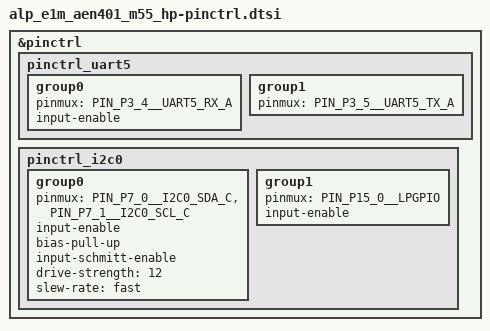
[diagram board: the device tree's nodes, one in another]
/*
 * Copyright (c) 2026 Alp Lab AB
 * SPDX-License-Identifier: Apache-2.0
 *
 * E1M-AEN401 (Alif Ensemble E4) Cortex-M55-HP carrier pin control.
 *
 * Console: the E1M edge "UART0" maps to Alif UART5 (P3_4 RX_A / P3_5 TX_A)
 * on the AEN module PCB; the Alp E1M-EVK carrier wires its USB-UART console
 * to it.  Confirmed against the shared AEN-family SoM pinout (common with
 * AEN801 -- same E1M connector mapping).
 *
 * BRD_I2C (the on-module RV-3028 / TMP112 bus) and the RV-3028 alarm pad are
 * copied from the generated AEN803 pin control: the AEN SKUs share one SoM
 * PCB.  Other pin groups are added alongside their drivers.
 */

#include <zephyr/dt-bindings/pinctrl/alif-ensemble-pinctrl.h>

&pinctrl {
	pinctrl_uart5: pinctrl_uart5 {
		group0 {
			pinmux = <PIN_P3_4__UART5_RX_A>;
			input-enable;
		};

		group1 {
			pinmux = <PIN_P3_5__UART5_TX_A>;
		};
	};
	/*
	 * BRD_I2C = SoC I2C0 function C: P7_0 SDA / P7_1 SCL,
	 * the on-module housekeeping bus (see the board .dts for the parts on it).
	 *
	 * BOTH pins get input-enable, in one group -- Alif's own DFP sets
	 * PADCTRL_READ_ENABLE on P7_0 AND P7_1.  With it on SDA only, the
	 * i2c_dw controller cannot SENSE SCL (clock-stretch detect / arbitration)
	 * and NACKs every address for a reason that looks electrical but is not.
	 *
	 * bias-pull-up is DSC=1, a REAL pull-up: pinctrl_soc.h's field comment
	 * (soc/alif/ensemble/pinctrl_soc.h:24) and its ALIF_PINCTRL_BIAS_CFG()
	 * macro (:44-48) both map bias-pull-up -> DSC=1 unconditionally -- there
	 * is NO inversion between the devicetree property and the DSC field, on
	 * this bus or the e1m_i2c0 one below (#2046 corrected that group's
	 * comment, which used to claim the opposite).  Do NOT copy the
	 * I2C2/EEPROM overlay's bias-pull-down: DSC=2 is a pull-DOWN, harmless
	 * there only because that bus has external carrier pull-ups (R137/R144).
	 * This net has NO external pull-up at all, so a pull-down would park both
	 * lines low and look like a busy bus.
	 *
	 * drive-open-drain is deliberately NOT set, so bit 23 [DRV] stays 0 =
	 * PUSH-PULL: the pad actively drives the high phase instead of relying on
	 * a pull-up this net does not have.  input-schmitt-enable + max
	 * drive-strength/slew-rate cover the resulting slow edges.  Bench-proven
	 * 2026-09-05 on E1M-AEN801 2626-R2 (same SoM PCB; not yet run on an AEN401): every non-response is a clean rc=-5
	 * (-EIO) NACK, zero -ETIMEDOUT, zero "User Abort".
	 */
	pinctrl_i2c0: pinctrl_i2c0 {
		group0 {
			pinmux = <PIN_P7_0__I2C0_SDA_C>, <PIN_P7_1__I2C0_SCL_C>;
			input-enable;
			bias-pull-up;
			input-schmitt-enable;
			drive-strength = <12>;
			slew-rate = "fast";
		};

		/*
		 * RTC_ALARM: the RV-3028 /INT line on P15_0 (lpgpio bit 0).
		 * Muxed + input-enabled here because snps,designware-gpio has no
		 * pinctrl-0 of its own (see this function's docstring); without it the
		 * pad input buffer stays off and the alarm reads 0 forever.
		 */
		group1 {
			pinmux = <PIN_P15_0__LPGPIO>;
			input-enable;
		};
	};
};
